AUTOSAR XML (schema 4-0-3)
standard types defined: Boolean, UInt32
package /AUTOSAR_Platform/DataConstrs
  range DC_Boolean: raw 0..1
package /PATAC/Facility/DataTypes/Implementation
  compu method COMPU_Boolean: 0=FALSE, 1=TRUE
  unit NoUnit: factor-si-to-unit=1, offset-si-to-unit=0
package /PATAC/MSM/ComponentTypes
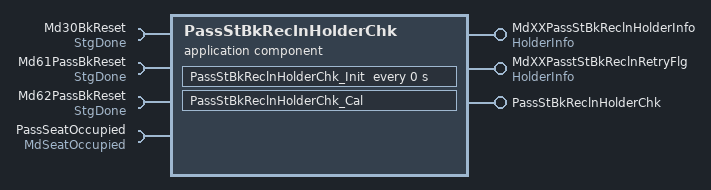
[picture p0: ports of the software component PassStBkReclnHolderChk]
  application sw component type PassStBkReclnHolderChk
    provide port MdXXPassStBkReclnHolderInfo: nonqueued-sender-com-spec{data-element=HolderInfo/Val, init-value=0}, provided-interface=HolderInfo
    provide port MdXXPasstStBkReclnRetryFlg: nonqueued-sender-com-spec{data-element=HolderInfo/Val, init-value=0}, provided-interface=HolderInfo
    provide port PassStBkReclnHolderChk: server-com-spec{operation=Cal, queue-length=1}, provided-interface=PassStBkReclnHolderChk
    4 x require port:
      Md30BkReset: nonqueued-receiver-com-spec{data-element=StgDone/Val, filter=data-filter-type=ALWAYS, init-value=0}, required-interface=StgDone
      Md61PassBkReset: nonqueued-receiver-com-spec{data-element=StgDone/Val, filter=data-filter-type=ALWAYS, init-value=0}, required-interface=StgDone
      Md62PassBkReset: nonqueued-receiver-com-spec{data-element=StgDone/Val, filter=data-filter-type=ALWAYS, init-value=0}, required-interface=StgDone
      PassSeatOccupied: nonqueued-receiver-com-spec{data-element=MdSeatOccupied/Val, filter=data-filter-type=ALWAYS, init-value=0}, required-interface=MdSeatOccupied
    behavior PassStBkReclnHolderChk_InternalBehavior
      operation invoked event OIT_PassStBkReclnHolderChk_Cal_PassStBkReclnHolderChk_Cal: start-on-event=PassStBkReclnHolderChk_Cal, operation=PassStBkReclnHolderChk.Cal
      timing event PassStBkReclnHolderChk_InitEvent: start-on-event=PassStBkReclnHolderChk_Init, period=0
      runnable PassStBkReclnHolderChk_Cal
        data-receive-point-by-arguments:
          4 x access:
            REC_Md30BkReset_Val: accessed-variable=Md30BkReset.Val
            REC_Md61PassBkReset_Val: accessed-variable=Md61PassBkReset.Val
            REC_Md62PassBkReset_Val: accessed-variable=Md62PassBkReset.Val
            REC_PassSeatOccupied_Val: accessed-variable=PassSeatOccupied.Val
        data-send-points:
          access SEND_MdXXPassStBkReclnHolderInfo_Val: accessed-variable=MdXXPassStBkReclnHolderInfo.Val
          access SEND_MdXXPasstStBkReclnRetryFlg_Val: accessed-variable=MdXXPasstStBkReclnRetryFlg.Val
      runnable PassStBkReclnHolderChk_Init
  swc implementation PassStBkReclnHolderChk_Implementation: behavior=PassStBkReclnHolderChk_InternalBehavior
    code-descriptors:
      code Default: artifact-descriptors=autosar-engineering-object={short-label=Default, category=SWSRC}
package /PATAC/MSM/ModeAdjust/PortInterface
  client server interface PassStBkReclnHolderChk
    operation Cal
  sender receiver interface HolderInfo: invalidation-policy{data-element=HolderInfo/Val, handle-invalid=DONT-INVALIDATE}
    data Val: type=UInt32
  sender receiver interface MdSeatOccupied: invalidation-policy{data-element=MdSeatOccupied/Val, handle-invalid=DONT-INVALIDATE}
    data Val: type=Boolean
  sender receiver interface StgDone: invalidation-policy{data-element=StgDone/Val, handle-invalid=DONT-INVALIDATE}
    data Val: type=Boolean
